# tviibh16m register map
Vendor: Infineon Technologies; Series: TVIIBH16M; File version: 1.0
CPU: CM7 r0p1, little endian, MPU, FPU, double-precision FPU, I-cache, D-cache, VTOR, ITCM, DTCM, 3 interrupt priority bits, 16 interrupts
Registers are 32-bit, read-write, reset 0x0 unless marked. A register's access mark holds for its fields unless they carry their own. Offsets are from the block's base; [hi:lo] are bit positions; lines under a group give offsets from that group; {n}, {i} and the like mark numbered series; 'fields as' and 'values as' point back to an identical list.

## PERI_MS — Peripheral interconnect, master interface
Base 0x40020000
{0x0+0x40*i} PPU_PR[{i}] (i=0..31) group — Programmable protection structure pair
  0x00 SL_ADDR reset not defined — Slave region, base address
    [31:2] ADDR30 — This field specifies the base address of the slave region. The region size is defined by SL_SIZE.REGION_SIZE. A region of n Bytes must be n Byte aligned. Therefore, some of the lesser significant address bits of ADDR30 must be '0's. E.g., a 64 KB address region (REGION_SIZE is '15') must be 64 KByte aligned, and ADDR30[13:0] must be '0's.
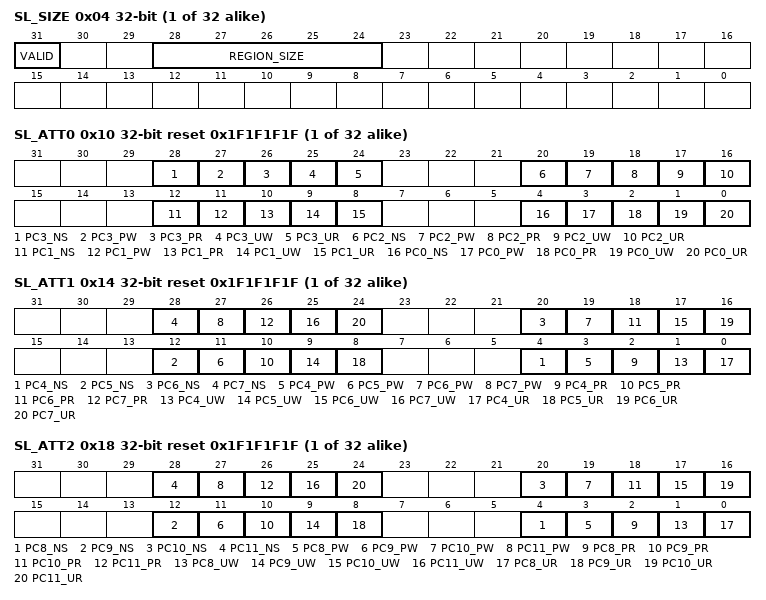
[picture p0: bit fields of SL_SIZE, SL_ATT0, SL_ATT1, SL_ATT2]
  0x04 SL_SIZE (reset mask 0x80000000) — Slave region, size
    [31] VALID — Slave region enable: '0': Disabled. A disabled region will never result in a match on the transfer address. '1': Enabled.
    [28:24] REGION_SIZE — This field specifies the size of the slave region: '0': Undefined. '1': 4 B region (this is the smallest region size). '2': 8 B region '3': 16 B region '4': 32 B region '5': 64 B region '6': 128 B region '7': 256 B region '8': 512 B region '9': 1 KB region '10': 2 KB region '11': 4 KB region '12': 8 KB region '13': 16 KB region '14': 32 KB region '15': 64 KB region '16': 128 KB region '17': 256 KB region '18': 512 KB region '19': 1 MB region '20': 2 MB region '21': 4 MB region '22': 8 MB region '23': 16 MB region '24': 32 MB region '25': 64 MB region '26': 128 MB region '27': 256 MB region '28': 512 MB region '29': 1 GB region '30': 2 GB region '31': 4 GB region
  0x10 SL_ATT0 reset 0x1F1F1F1F — Slave attributes 0
    [28] PC3_NS — Protection context 3, non-secure.
    [27] PC3_PW — Protection context 3, privileged write enable.
    [26] PC3_PR — Protection context 3, privileged read enable.
    [25] PC3_UW — Protection context 3, user write enable.
    [24] PC3_UR — Protection context 3, user read enable.
    [20] PC2_NS — Protection context 2, non-secure.
    [19] PC2_PW — Protection context 2, privileged write enable.
    [18] PC2_PR — Protection context 2, privileged read enable.
    [17] PC2_UW — Protection context 2, user write enable.
    [16] PC2_UR — Protection context 2, user read enable.
    [12] PC1_NS — Protection context 1, non-secure.
    [11] PC1_PW — Protection context 1, privileged write enable.
    [10] PC1_PR — Protection context 1, privileged read enable.
    [9] PC1_UW — Protection context 1, user write enable.
    [8] PC1_UR — Protection context 1, user read enable.
    [4] PC0_NS ro — Protection context 0, non-secure: '0': Secure (secure accesses allowed, non-secure access NOT allowed). '1': Non-secure (both secure and non-secure accesses allowed).
    [3] PC0_PW ro — Protection context 0, privileged write enable: '0': Disabled (privileged, write accesses are NOT allowed). '1': Enabled (privileged, write accesses are allowed).
    [2] PC0_PR ro — Protection context 0, privileged read enable: '0': Disabled (privileged, read accesses are NOT allowed). '1': Enabled (privileged, read accesses are allowed).
    [1] PC0_UW ro — Protection context 0, user write enable: '0': Disabled (user, write accesses are NOT allowed). '1': Enabled (user, write accesses are allowed).
    [0] PC0_UR ro — Protection context 0, user read enable: '0': Disabled (user, read accesses are NOT allowed). '1': Enabled (user, read accesses are allowed).
  0x14 SL_ATT1 reset 0x1F1F1F1F — Slave attributes 1
    [8n-28] PC{n}_NS (n=4..7) — Protection context {n}, non-secure.
    [8n-29] PC{n}_PW (n=4..7) — Protection context {n}, privileged write enable.
    [8n-30] PC{n}_PR (n=4..7) — Protection context {n}, privileged read enable.
    [8n-31] PC{n}_UW (n=4..7) — Protection context {n}, user write enable.
    [8n-32] PC{n}_UR (n=4..7) — Protection context {n}, user read enable.
  0x18 SL_ATT2 reset 0x1F1F1F1F — Slave attributes 2
    [8n-60] PC{n}_NS (n=8..11) — Protection context {n}, non-secure.
    [8n-61] PC{n}_PW (n=8..11) — Protection context {n}, privileged write enable.
    [8n-62] PC{n}_PR (n=8..11) — Protection context {n}, privileged read enable.
    [8n-63] PC{n}_UW (n=8..11) — Protection context {n}, user write enable.
    [8n-64] PC{n}_UR (n=8..11) — Protection context {n}, user read enable.
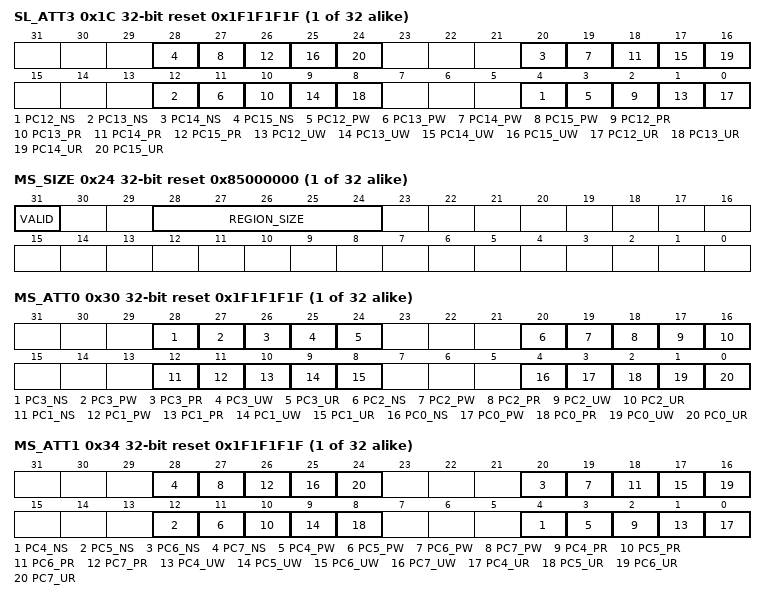
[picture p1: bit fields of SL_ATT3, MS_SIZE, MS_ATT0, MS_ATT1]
  0x1C SL_ATT3 reset 0x1F1F1F1F — Slave attributes 3
    [8n-92] PC{n}_NS (n=12..15) — Protection context {n}, non-secure.
    [8n-93] PC{n}_PW (n=12..15) — Protection context {n}, privileged write enable.
    [8n-94] PC{n}_PR (n=12..15) — Protection context {n}, privileged read enable.
    [8n-95] PC{n}_UW (n=12..15) — Protection context {n}, user write enable.
    [8n-96] PC{n}_UR (n=12..15) — Protection context {n}, user read enable.
  0x20 MS_ADDR ro — Master region, base address
    [31:6] ADDR26 — This field specifies the base address of the master region. The base address of the region is the address of the SL_ADDR register.
  0x24 MS_SIZE ro reset 0x85000000 — Master region, size
    [31] VALID — Master region enable: '1': Enabled.
    [28:24] REGION_SIZE — This field specifies the size of the master region: '5': 64 B region The master region includes the SL_ADDR, SL_SIZE, SL_ATT0, ..., SL_ATT3, MS_ADDR, MS_SIZE, MS_ATT0, ..., MS_ATT3 registers. Therefore, the access privileges for all these registers is determined by MS_ATT0, ..., MS_ATT3.
  0x30 MS_ATT0 reset 0x1F1F1F1F — Master attributes 0
    [28] PC3_NS — Protection context 3, non-secure.
    [27] PC3_PW — Protection context 3, privileged write enable.
    [26] PC3_PR ro — Protection context 3, privileged read enable.
    [25] PC3_UW — Protection context 3, user write enable.
    [24] PC3_UR ro — Protection context 3, user read enable.
    [20] PC2_NS — Protection context 2, non-secure.
    [19] PC2_PW — Protection context 2, privileged write enable.
    [18] PC2_PR ro — Protection context 2, privileged read enable.
    [17] PC2_UW — Protection context 2, user write enable.
    [16] PC2_UR ro — Protection context 2, user read enable.
    [12] PC1_NS — Protection context 1, non-secure.
    [11] PC1_PW — Protection context 1, privileged write enable.
    [10] PC1_PR ro — Protection context 1, privileged read enable.
    [9] PC1_UW — Protection context 1, user write enable.
    [8] PC1_UR ro — Protection context 1, user read enable.
    [4] PC0_NS ro — Protection context 0, non-secure: '0': Secure (secure accesses allowed, non-secure access NOT allowed). '1': Non-secure (both secure and non-secure accesses allowed).
    [3] PC0_PW ro — Protection context 0, privileged write enable: '0': Disabled (privileged, write accesses are NOT allowed). '1': Enabled (privileged, write accesses are allowed).
    [2] PC0_PR ro — Protection context 0, privileged read enable: '0': Disabled (privileged, read accesses are NOT allowed). '1': Enabled (privileged, read accesses are allowed).
    [1] PC0_UW ro — Protection context 0, user write enable: '0': Disabled (user, write accesses are NOT allowed). '1': Enabled (user, write accesses are allowed).
    [0] PC0_UR ro — Protection context 0, user read enable: '0': Disabled (user, read accesses are NOT allowed). '1': Enabled (user, read accesses are allowed).
  0x34 MS_ATT1 reset 0x1F1F1F1F — Master attributes 1
    [8n-28] PC{n}_NS (n=4..7) — Protection context {n}, non-secure.
    [8n-29] PC{n}_PW (n=4..7) — Protection context {n}, privileged write enable.
    [8n-30] PC{n}_PR ro (n=4..7) — Protection context {n}, privileged read enable.
    [8n-31] PC{n}_UW (n=4..7) — Protection context {n}, user write enable.
    [8n-32] PC{n}_UR ro (n=4..7) — Protection context {n}, user read enable.
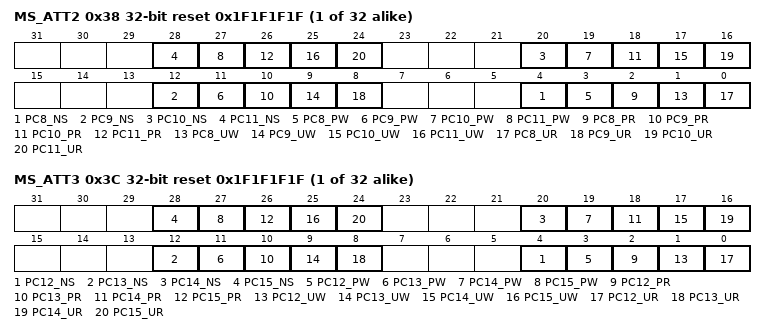
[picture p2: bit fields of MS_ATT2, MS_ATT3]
  0x38 MS_ATT2 reset 0x1F1F1F1F — Master attributes 2
    [8n-60] PC{n}_NS (n=8..11) — Protection context {n}, non-secure.
    [8n-61] PC{n}_PW (n=8..11) — Protection context {n}, privileged write enable.
    [8n-62] PC{n}_PR ro (n=8..11) — Protection context {n}, privileged read enable.
    [8n-63] PC{n}_UW (n=8..11) — Protection context {n}, user write enable.
    [8n-64] PC{n}_UR ro (n=8..11) — Protection context {n}, user read enable.
  0x3C MS_ATT3 reset 0x1F1F1F1F — Master attributes 3
    [8n-92] PC{n}_NS (n=12..15) — Protection context {n}, non-secure.
    [8n-93] PC{n}_PW (n=12..15) — Protection context {n}, privileged write enable.
    [8n-94] PC{n}_PR ro (n=12..15) — Protection context {n}, privileged read enable.
    [8n-95] PC{n}_UW (n=12..15) — Protection context {n}, user write enable.
    [8n-96] PC{n}_UR ro (n=12..15) — Protection context {n}, user read enable.
{0x800+0x40*i} PPU_FX[{i}] (i=0..745) group — Fixed protection structure pair
  0x00 SL_ADDR ro — Slave region, base address
    fields as PPU_PR[0].SL_ADDR
  0x04 SL_SIZE ro reset 0x80000000 — Slave region, size
    fields as PPU_PR[0].SL_SIZE
  0x10 SL_ATT0 reset 0x1F1F1F1F — Slave attributes 0
    fields as PPU_PR[0].SL_ATT0
  0x14 SL_ATT1 reset 0x1F1F1F1F — Slave attributes 1
    fields as PPU_PR[0].SL_ATT1
  0x18 SL_ATT2 reset 0x1F1F1F1F — Slave attributes 2
    fields as PPU_PR[0].SL_ATT2
  0x1C SL_ATT3 reset 0x1F1F1F1F — Slave attributes 3
    fields as PPU_PR[0].SL_ATT3
  0x20 MS_ADDR ro — Master region, base address
    fields as PPU_PR[0].MS_ADDR
  0x24 MS_SIZE ro reset 0x85000000 — Master region, size
    fields as PPU_PR[0].MS_SIZE
  0x30 MS_ATT0 reset 0x1F1F1F1F — Master attributes 0
    fields as PPU_PR[0].MS_ATT0
  0x34 MS_ATT1 reset 0x1F1F1F1F — Master attributes 1
    fields as PPU_PR[0].MS_ATT1
  0x38 MS_ATT2 reset 0x1F1F1F1F — Master attributes 2
    fields as PPU_PR[0].MS_ATT2
  0x3C MS_ATT3 reset 0x1F1F1F1F — Master attributes 3
    fields as PPU_PR[0].MS_ATT3

## Notices in the file
(c) 2016-2026, Infineon Technologies AG or an affiliate of
Infineon Technologies AG.
SPDX-License-Identifier: Apache-2.0
Licensed under the Apache License, Version 2.0 (the "License");
you may not use this file except in compliance with the License.
You may obtain a copy of the License at
http://www.apache.org/licenses/LICENSE-2.0
Unless required by applicable law or agreed to in writing, software
distributed under the License is distributed on an "AS IS" BASIS,
WITHOUT WARRANTIES OR CONDITIONS OF ANY KIND, either express or implied.
See the License for the specific language governing permissions and
limitations under the License.
